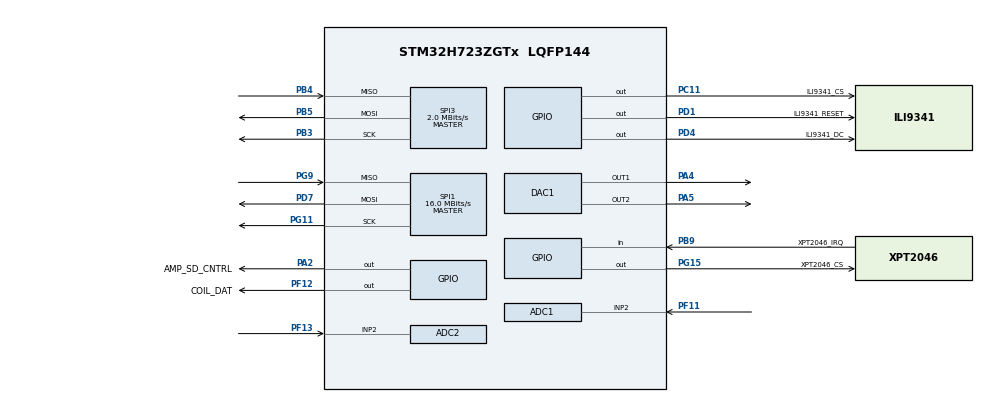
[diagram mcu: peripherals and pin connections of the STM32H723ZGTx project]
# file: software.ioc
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ADC1.Channel-0\#ChannelRegularConversion=ADC_CHANNEL_2
ADC1.ClockPrescaler=ADC_CLOCK_ASYNC_DIV2
ADC1.ConversionDataManagement=ADC_CONVERSIONDATA_DMA_CIRCULAR
ADC1.DMAAccessModeView=ENABLE
ADC1.ExternalTrigConv=ADC_EXTERNALTRIG_T2_TRGO
ADC1.Mode=ADC_DUALMODE_REGSIMULT
ADC1.NbrOfConversionFlag=1
ADC1.OffsetNumber-0\#ChannelRegularConversion=ADC_OFFSET_NONE
ADC1.OffsetSignedSaturation-0\#ChannelRegularConversion=DISABLE
ADC1.Rank-0\#ChannelRegularConversion=1
ADC1.Resolution=ADC_RESOLUTION_12B
ADC1.SamplingTime-0\#ChannelRegularConversion=ADC_SAMPLETIME_1CYCLE_5
ADC1.TwoSamplingDelay=ADC_TWOSAMPLINGDELAY_1CYCLE
ADC1.master=1
ADC2.Channel-0\#ChannelRegularConversion=ADC_CHANNEL_2
ADC2.ClockPrescaler=ADC_CLOCK_ASYNC_DIV2
ADC2.DMAAccessModeView=ENABLE
ADC2.Mode=ADC_DUALMODE_REGSIMULT
ADC2.NbrOfConversionFlag=1
ADC2.OffsetNumber-0\#ChannelRegularConversion=ADC_OFFSET_NONE
ADC2.OffsetSignedSaturation-0\#ChannelRegularConversion=DISABLE
ADC2.Rank-0\#ChannelRegularConversion=1
ADC2.Resolution=ADC_RESOLUTION_12B
ADC2.SamplingTime-0\#ChannelRegularConversion=ADC_SAMPLETIME_1CYCLE_5
CORTEX_M7.default_mode_Activation=1
DAC1.DAC1_OutputBuffer-DAC_OUT1=DAC_OUTPUTBUFFER_ENABLE
DAC1.DAC_Channel-DAC_OUT1=DAC_CHANNEL_1
DAC1.DAC_Channel-DAC_OUT2=DAC_CHANNEL_2
DAC1.DAC_Trigger-DAC_OUT1=DAC_TRIGGER_T2_TRGO
DAC1.DAC_Trigger-DAC_OUT2=DAC_TRIGGER_T2_TRGO
Dma.ADC1.0.Direction=DMA_PERIPH_TO_MEMORY
Dma.ADC1.0.EventEnable=DISABLE
Dma.ADC1.0.FIFOMode=DMA_FIFOMODE_DISABLE
Dma.ADC1.0.Instance=DMA1_Stream2
Dma.ADC1.0.MemDataAlignment=DMA_MDATAALIGN_WORD
Dma.ADC1.0.MemInc=DMA_MINC_ENABLE
Dma.ADC1.0.Mode=DMA_CIRCULAR
Dma.ADC1.0.PeriphDataAlignment=DMA_PDATAALIGN_WORD
Dma.ADC1.0.PeriphInc=DMA_PINC_DISABLE
Dma.ADC1.0.Polarity=HAL_DMAMUX_REQ_GEN_RISING
Dma.ADC1.0.Priority=DMA_PRIORITY_LOW
Dma.ADC1.0.RequestNumber=1
Dma.ADC1.0.SignalID=NONE
Dma.ADC1.0.SyncEnable=DISABLE
Dma.ADC1.0.SyncPolarity=HAL_DMAMUX_SYNC_NO_EVENT
Dma.ADC1.0.SyncRequestNumber=1
Dma.ADC1.0.SyncSignalID=NONE
Dma.DAC1_CH1.2.Direction=DMA_MEMORY_TO_PERIPH
Dma.DAC1_CH1.2.EventEnable=DISABLE
Dma.DAC1_CH1.2.FIFOMode=DMA_FIFOMODE_DISABLE
Dma.DAC1_CH1.2.Instance=DMA1_Stream0
Dma.DAC1_CH1.2.MemDataAlignment=DMA_MDATAALIGN_WORD
Dma.DAC1_CH1.2.MemInc=DMA_MINC_ENABLE
Dma.DAC1_CH1.2.Mode=DMA_CIRCULAR
Dma.DAC1_CH1.2.PeriphDataAlignment=DMA_PDATAALIGN_WORD
Dma.DAC1_CH1.2.PeriphInc=DMA_PINC_DISABLE
Dma.DAC1_CH1.2.Polarity=HAL_DMAMUX_REQ_GEN_RISING
Dma.DAC1_CH1.2.Priority=DMA_PRIORITY_LOW
Dma.DAC1_CH1.2.RequestNumber=1
Dma.DAC1_CH1.2.SignalID=NONE
Dma.DAC1_CH1.2.SyncEnable=DISABLE
Dma.DAC1_CH1.2.SyncPolarity=HAL_DMAMUX_SYNC_NO_EVENT
Dma.DAC1_CH1.2.SyncRequestNumber=1
Dma.DAC1_CH1.2.SyncSignalID=NONE
Dma.DAC1_CH2.3.Direction=DMA_MEMORY_TO_PERIPH
Dma.DAC1_CH2.3.EventEnable=DISABLE
Dma.DAC1_CH2.3.FIFOMode=DMA_FIFOMODE_DISABLE
Dma.DAC1_CH2.3.Instance=DMA1_Stream3
Dma.DAC1_CH2.3.MemDataAlignment=DMA_MDATAALIGN_WORD
Dma.DAC1_CH2.3.MemInc=DMA_MINC_ENABLE
Dma.DAC1_CH2.3.Mode=DMA_CIRCULAR
Dma.DAC1_CH2.3.PeriphDataAlignment=DMA_PDATAALIGN_WORD
Dma.DAC1_CH2.3.PeriphInc=DMA_PINC_DISABLE
Dma.DAC1_CH2.3.Polarity=HAL_DMAMUX_REQ_GEN_RISING
Dma.DAC1_CH2.3.Priority=DMA_PRIORITY_LOW
Dma.DAC1_CH2.3.RequestNumber=1
Dma.DAC1_CH2.3.SignalID=NONE
Dma.DAC1_CH2.3.SyncEnable=DISABLE
Dma.DAC1_CH2.3.SyncPolarity=HAL_DMAMUX_SYNC_NO_EVENT
Dma.DAC1_CH2.3.SyncRequestNumber=1
Dma.DAC1_CH2.3.SyncSignalID=NONE
Dma.Request0=ADC1
Dma.Request1=SPI1_TX
Dma.Request2=DAC1_CH1
Dma.Request3=DAC1_CH2
Dma.SPI1_TX.1.Direction=DMA_MEMORY_TO_PERIPH
Dma.SPI1_TX.1.EventEnable=DISABLE
Dma.SPI1_TX.1.FIFOMode=DMA_FIFOMODE_DISABLE
Dma.SPI1_TX.1.Instance=DMA1_Stream1
Dma.SPI1_TX.1.MemDataAlignment=DMA_MDATAALIGN_BYTE
Dma.SPI1_TX.1.MemInc=DMA_MINC_ENABLE
Dma.SPI1_TX.1.Mode=DMA_NORMAL
Dma.SPI1_TX.1.PeriphDataAlignment=DMA_PDATAALIGN_BYTE
Dma.SPI1_TX.1.PeriphInc=DMA_PINC_DISABLE
Dma.SPI1_TX.1.Polarity=HAL_DMAMUX_REQ_GEN_RISING
Dma.SPI1_TX.1.Priority=DMA_PRIORITY_LOW
Dma.SPI1_TX.1.RequestNumber=1
Dma.SPI1_TX.1.SignalID=NONE
Dma.SPI1_TX.1.SyncEnable=DISABLE
Dma.SPI1_TX.1.SyncPolarity=HAL_DMAMUX_SYNC_NO_EVENT
Dma.SPI1_TX.1.SyncRequestNumber=1
Dma.SPI1_TX.1.SyncSignalID=NONE
FREERTOS.BinarySemaphores01=AudioSemaphore,Static,AudioSemaphoreControlBlock,Available
FREERTOS.HEAP_NUMBER=4
FREERTOS.Mutexes01=LvMutex,Static,LvMutexControlBlock,Available
FREERTOS.Queues01=InputFlagQueue,1,uint32_t,0,Static,InputFlagQueueBuffer,InputFlagQueueControlBlock
FREERTOS.Tasks01=SignalProcessing,24,1000,SignalProcessingTask,As weak,NULL,Static,SignalProcessingBuffer,SignalProcessingControlBlock;ProduceAudio,23,128,ProduceAudioTask,As weak,NULL,Static,ProduceAudioBuffer,ProduceAudioControlBlock;lvHandler,48,5000,LvHandlerTask,As weak,NULL,Static,lvHandlerBuffer,lvHandlerControlBlock
FREERTOS.configMAX_TASK_NAME_LEN=24
FREERTOS.configUSE_IDLE_HOOK=0
FREERTOS.configUSE_NEWLIB_REENTRANT=1
Mcu.Family=STM32H7
Mcu.Name=STM32H723ZGTx
Mcu.Package=LQFP144
NVIC.DMA1_Stream0_IRQn=true\:14\:0\:true\:false\:true\:true\:false\:true\:true
NVIC.DMA1_Stream1_IRQn=true\:14\:0\:true\:false\:true\:true\:false\:true\:true
NVIC.DMA1_Stream2_IRQn=true\:14\:0\:true\:false\:true\:true\:false\:true\:true
NVIC.DMA1_Stream3_IRQn=true\:14\:0\:true\:false\:true\:true\:false\:true\:true
NVIC.PriorityGroup=NVIC_PRIORITYGROUP_4
NVIC.SPI1_IRQn=true\:14\:0\:true\:false\:true\:true\:false\:true\:true
NVIC.TIM1_UP_IRQn=true\:15\:0\:false\:false\:true\:false\:false\:true\:true
NVIC.TimeBase=TIM1_UP_IRQn
NVIC.TimeBaseIP=TIM1
PA13(JTMS/SWDIO).Mode=Serial_Wire
PA13(JTMS/SWDIO).Signal=DEBUG_JTMS-SWDIO
PA14(JTCK/SWCLK).Mode=Serial_Wire
PA14(JTCK/SWCLK).Signal=DEBUG_JTCK-SWCLK
PA2.GPIO_Label=AMP_SD_CNTRL
PA2.PinState=GPIO_PIN_RESET
PA2.Signal=GPIO_Output
PA4.Signal=COMP_DAC11_group
PA5.Signal=COMP_DAC12_group
PB3(JTDO/TRACESWO).Mode=Full_Duplex_Master
PB3(JTDO/TRACESWO).Signal=SPI3_SCK
PB4(NJTRST).Mode=Full_Duplex_Master
PB4(NJTRST).Signal=SPI3_MISO
PB5.Mode=Full_Duplex_Master
PB5.Signal=SPI3_MOSI
PB9.GPIO_Label=XPT2046_IRQ
PB9.GPIO_PuPd=GPIO_PULLUP
PB9.Signal=GPIO_Input
PC11.GPIO_Label=ILI9341_CS
PC11.PinState=GPIO_PIN_SET
PC11.Signal=GPIO_Output
PC14-OSC32_IN.Mode=LSE-External-Oscillator
PC14-OSC32_IN.Signal=RCC_OSC32_IN
PC15-OSC32_OUT.Mode=LSE-External-Oscillator
PC15-OSC32_OUT.Signal=RCC_OSC32_OUT
PD1.GPIO_Label=ILI9341_RESET
PD1.PinState=GPIO_PIN_SET
PD1.Signal=GPIO_Output
PD4.GPIO_Label=ILI9341_DC
PD4.PinState=GPIO_PIN_SET
PD4.Signal=GPIO_Output
PD7.Mode=Full_Duplex_Master
PD7.Signal=SPI1_MOSI
PF11.Mode=IN2-Single-Ended
PF11.Signal=ADC1_INP2
PF12.GPIO_Label=COIL_DAT
PF12.GPIO_Speed=GPIO_SPEED_FREQ_VERY_HIGH
PF12.Signal=GPIO_Output
PF13.Mode=IN2-Single-Ended
PF13.Signal=ADC2_INP2
PG11.Mode=Full_Duplex_Master
PG11.Signal=SPI1_SCK
PG15.GPIO_Label=XPT2046_CS
PG15.PinState=GPIO_PIN_SET
PG15.Signal=GPIO_Output
PG9.Mode=Full_Duplex_Master
PG9.Signal=SPI1_MISO
PH0-OSC_IN.Mode=HSE-External-Oscillator
PH0-OSC_IN.Signal=RCC_OSC_IN
PH1-OSC_OUT.Mode=HSE-External-Oscillator
PH1-OSC_OUT.Signal=RCC_OSC_OUT
ProjectManager.HeapSize=0x500
ProjectManager.StackSize=0x400
ProjectManager.TargetToolchain=STM32CubeIDE
RCC.ADCFreq_Value=50000000
RCC.APB1Freq_Value=137500000
RCC.APB2Freq_Value=137500000
RCC.APB3Freq_Value=137500000
RCC.APB4Freq_Value=137500000
RCC.CortexFreq_Value=550000000
RCC.D1PPRE=RCC_APB3_DIV2
RCC.D2PPRE1=RCC_APB1_DIV2
RCC.D2PPRE2=RCC_APB2_DIV2
RCC.D3PPRE=RCC_APB4_DIV2
RCC.DIVM1=2
RCC.DIVM2=2
RCC.DIVN1=44
RCC.DIVN2=16
RCC.DIVP1=1
RCC.DIVP2=4
RCC.DIVQ1=37
RCC.HCLKFreq_Value=275000000
RCC.HPRE=RCC_HCLK_DIV2
RCC.PLL2FRACN=0
RCC.PLL3FRACN=0
RCC.PLLFRACN=0
RCC.PLLSourceVirtual=RCC_PLLSOURCE_HSE
RCC.SPI123CLockSelection=RCC_SPI123CLKSOURCE_CLKP
RCC.SYSCLKFreq_VALUE=550000000
RCC.SYSCLKSource=RCC_SYSCLKSOURCE_PLLCLK
RCC.USBFreq_Value=14864864.864864865
SH.COMP_DAC11_group.0=DAC1_OUT1,DAC_OUT1
SH.COMP_DAC12_group.0=DAC1_OUT2,DAC_OUT2
SPI1.BaudRatePrescaler=SPI_BAUDRATEPRESCALER_4
SPI1.CalculateBaudRate=16.0 MBits/s
SPI1.DataSize=SPI_DATASIZE_8BIT
SPI1.Direction=SPI_DIRECTION_2LINES
SPI1.Mode=SPI_MODE_MASTER
SPI1.VirtualType=VM_MASTER
SPI3.BaudRatePrescaler=SPI_BAUDRATEPRESCALER_32
SPI3.CalculateBaudRate=2.0 MBits/s
SPI3.DataSize=SPI_DATASIZE_8BIT
SPI3.Direction=SPI_DIRECTION_2LINES
SPI3.Mode=SPI_MODE_MASTER
SPI3.VirtualType=VM_MASTER
STMicroelectronics.X-CUBE-ALGOBUILD.1.4.0.LibraryCcDSPOoLibraryJjDSPOoLibrary=true
TIM2.Period=1467-1
TIM2.Prescaler=0
TIM2.TIM_MasterOutputTrigger=TIM_TRGO_UPDATE
VP_FREERTOS_VS_CMSIS_V2.Mode=CMSIS_V2
VP_MEMORYMAP_VS_MEMORYMAP.Mode=CurAppReg
VP_STMicroelectronics.X-CUBE-ALGOBUILD_VS_DSPOoLibraryJjLibrary_1.4.0_1.4.0.Mode=DSPOoLibraryJjLibrary
VP_SYS_VS_tim1.Mode=TIM1
VP_TIM2_VS_ClockSourceINT.Mode=Internal
board=custom

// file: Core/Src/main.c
/* USER CODE BEGIN Header */
/**
  ******************************************************************************
  * @file           : main.c
  * @brief          : Main program body
  ******************************************************************************
  * @attention
  *
  * Copyright (c) 2024 STMicroelectronics.
  * All rights reserved.
  *
  * This software is licensed under terms that can be found in the LICENSE file
  * in the root directory of this software component.
  * If no LICENSE file comes with this software, it is provided AS-IS.
  *
  ******************************************************************************
  */
/* USER CODE END Header */
#include "main.h"
#include "cmsis_os.h"
#include "adc.h"
#include "dac.h"
#include "dma.h"
#include "memorymap.h"
#include "spi.h"
#include "tim.h"
#include "gpio.h"

/* USER CODE BEGIN Includes */

#include "lvgl.h"
#include "display.h"
#include "ui.h"

#include "app_signal.h"

/* USER CODE END Includes */

void SystemClock_Config(void);
void PeriphCommonClock_Config(void);
static void MPU_Config(void);
void MX_FREERTOS_Init(void);

int main(void)
{

  /* MPU Configuration--------------------------------------------------------*/
  MPU_Config();

  /* MCU Configuration--------------------------------------------------------*/

  /* Reset of all peripherals, Initializes the Flash interface and the Systick. */
  HAL_Init();

  /* Configure the system clock */
  SystemClock_Config();

  /* Configure the peripherals common clocks */
  PeriphCommonClock_Config();

  /* Initialize all configured peripherals */
  MX_GPIO_Init();
  MX_DMA_Init();
  MX_SPI3_Init();
  MX_ADC1_Init();
  MX_ADC2_Init();
  MX_DAC1_Init();
  MX_SPI1_Init();
  MX_TIM2_Init();
  /* USER CODE BEGIN 2 */

	dp_init();

	dp_lvgl_init();

	ui_init();

	sig_start(&sig_handle);

  /* USER CODE END 2 */

  /* Init scheduler */
  osKernelInitialize();

  /* Call init function for freertos objects (in cmsis_os2.c) */
  MX_FREERTOS_Init();

  /* Start scheduler */
  osKernelStart();

  /* We should never get here as control is now taken by the scheduler */

  /* Infinite loop */
  while (1)
  {

  }
}

void SystemClock_Config(void)
{
  RCC_OscInitTypeDef RCC_OscInitStruct = {0};
  RCC_ClkInitTypeDef RCC_ClkInitStruct = {0};

  /** Supply configuration update enable
  */
  HAL_PWREx_ConfigSupply(PWR_LDO_SUPPLY);

  /** Configure the main internal regulator output voltage
  */
  __HAL_PWR_VOLTAGESCALING_CONFIG(PWR_REGULATOR_VOLTAGE_SCALE0);

  while(!__HAL_PWR_GET_FLAG(PWR_FLAG_VOSRDY)) {}

  /** Initializes the RCC Oscillators according to the specified parameters
  * in the RCC_OscInitTypeDef structure.
  */
  RCC_OscInitStruct.OscillatorType = RCC_OSCILLATORTYPE_HSI|RCC_OSCILLATORTYPE_HSE;
  RCC_OscInitStruct.HSEState = RCC_HSE_ON;
  RCC_OscInitStruct.HSIState = RCC_HSI_DIV1;
  RCC_OscInitStruct.HSICalibrationValue = 64;
  RCC_OscInitStruct.PLL.PLLState = RCC_PLL_ON;
  RCC_OscInitStruct.PLL.PLLSource = RCC_PLLSOURCE_HSE;
  RCC_OscInitStruct.PLL.PLLM = 2;
  RCC_OscInitStruct.PLL.PLLN = 44;
  RCC_OscInitStruct.PLL.PLLP = 1;
  RCC_OscInitStruct.PLL.PLLQ = 37;
  RCC_OscInitStruct.PLL.PLLR = 2;
  RCC_OscInitStruct.PLL.PLLRGE = RCC_PLL1VCIRANGE_3;
  RCC_OscInitStruct.PLL.PLLVCOSEL = RCC_PLL1VCOWIDE;
  RCC_OscInitStruct.PLL.PLLFRACN = 0;
  if (HAL_RCC_OscConfig(&RCC_OscInitStruct) != HAL_OK)
  {
    Error_Handler();
  }

  /** Initializes the CPU, AHB and APB buses clocks
  */
  RCC_ClkInitStruct.ClockType = RCC_CLOCKTYPE_HCLK|RCC_CLOCKTYPE_SYSCLK
                              |RCC_CLOCKTYPE_PCLK1|RCC_CLOCKTYPE_PCLK2
                              |RCC_CLOCKTYPE_D3PCLK1|RCC_CLOCKTYPE_D1PCLK1;
  RCC_ClkInitStruct.SYSCLKSource = RCC_SYSCLKSOURCE_PLLCLK;
  RCC_ClkInitStruct.SYSCLKDivider = RCC_SYSCLK_DIV1;
  RCC_ClkInitStruct.AHBCLKDivider = RCC_HCLK_DIV2;
  RCC_ClkInitStruct.APB3CLKDivider = RCC_APB3_DIV2;
  RCC_ClkInitStruct.APB1CLKDivider = RCC_APB1_DIV2;
  RCC_ClkInitStruct.APB2CLKDivider = RCC_APB2_DIV2;
  RCC_ClkInitStruct.APB4CLKDivider = RCC_APB4_DIV2;

  if (HAL_RCC_ClockConfig(&RCC_ClkInitStruct, FLASH_LATENCY_3) != HAL_OK)
  {
    Error_Handler();
  }
}

void PeriphCommonClock_Config(void)
{
  RCC_PeriphCLKInitTypeDef PeriphClkInitStruct = {0};

  /** Initializes the peripherals clock
  */
  PeriphClkInitStruct.PeriphClockSelection = RCC_PERIPHCLK_ADC|RCC_PERIPHCLK_CKPER;
  PeriphClkInitStruct.PLL2.PLL2M = 2;
  PeriphClkInitStruct.PLL2.PLL2N = 16;
  PeriphClkInitStruct.PLL2.PLL2P = 4;
  PeriphClkInitStruct.PLL2.PLL2Q = 2;
  PeriphClkInitStruct.PLL2.PLL2R = 2;
  PeriphClkInitStruct.PLL2.PLL2RGE = RCC_PLL2VCIRANGE_3;
  PeriphClkInitStruct.PLL2.PLL2VCOSEL = RCC_PLL2VCOWIDE;
  PeriphClkInitStruct.PLL2.PLL2FRACN = 0;
  PeriphClkInitStruct.CkperClockSelection = RCC_CLKPSOURCE_HSI;
  PeriphClkInitStruct.AdcClockSelection = RCC_ADCCLKSOURCE_PLL2;
  if (HAL_RCCEx_PeriphCLKConfig(&PeriphClkInitStruct) != HAL_OK)
  {
    Error_Handler();
  }
}

/* USER CODE BEGIN 4 */

void HAL_SPI_TxCpltCallback(SPI_HandleTypeDef *hspi)
{
	if( hspi == ili9341_spi )
	{
		ILI9341_SPICmpltHandler();
	}
}

/* USER CODE END 4 */

 /* MPU Configuration */

void MPU_Config(void)
{
  MPU_Region_InitTypeDef MPU_InitStruct = {0};

  /* Disables the MPU */
  HAL_MPU_Disable();

  /** Initializes and configures the Region and the memory to be protected
  */
  MPU_InitStruct.Enable = MPU_REGION_ENABLE;
  MPU_InitStruct.Number = MPU_REGION_NUMBER0;
  MPU_InitStruct.BaseAddress = 0x0;
  MPU_InitStruct.Size = MPU_REGION_SIZE_4GB;
  MPU_InitStruct.SubRegionDisable = 0x87;
  MPU_InitStruct.TypeExtField = MPU_TEX_LEVEL0;
  MPU_InitStruct.AccessPermission = MPU_REGION_NO_ACCESS;
  MPU_InitStruct.DisableExec = MPU_INSTRUCTION_ACCESS_DISABLE;
  MPU_InitStruct.IsShareable = MPU_ACCESS_SHAREABLE;
  MPU_InitStruct.IsCacheable = MPU_ACCESS_NOT_CACHEABLE;
  MPU_InitStruct.IsBufferable = MPU_ACCESS_NOT_BUFFERABLE;

  HAL_MPU_ConfigRegion(&MPU_InitStruct);
  /* Enables the MPU */
  HAL_MPU_Enable(MPU_PRIVILEGED_DEFAULT);

}

void HAL_TIM_PeriodElapsedCallback(TIM_HandleTypeDef *htim)
{
  if (htim->Instance == TIM1) {
    HAL_IncTick();
  }
}

void Error_Handler(void)
{
  __disable_irq();
  while (1)
  {
  }
}

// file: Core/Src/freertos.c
/* USER CODE BEGIN Header */
/**
  ******************************************************************************
  * File Name          : freertos.c
  * Description        : Code for freertos applications
  ******************************************************************************
  * @attention
  *
  * Copyright (c) 2024 STMicroelectronics.
  * All rights reserved.
  *
  * This software is licensed under terms that can be found in the LICENSE file
  * in the root directory of this software component.
  * If no LICENSE file comes with this software, it is provided AS-IS.
  *
  ******************************************************************************
  */
/* USER CODE END Header */

#include "FreeRTOS.h"
#include "task.h"
#include "main.h"
#include "cmsis_os.h"

typedef StaticTask_t osStaticThreadDef_t;
typedef StaticQueue_t osStaticMessageQDef_t;
typedef StaticSemaphore_t osStaticMutexDef_t;
typedef StaticSemaphore_t osStaticSemaphoreDef_t;

/* USER CODE BEGIN PM */

#define MS_TO_TICKS(ms) ((ms * osKernelGetTickFreq()) / 1000)

/* USER CODE END PM */

/* Definitions for SignalProcessing */
osThreadId_t SignalProcessingHandle;
uint32_t SignalProcessingBuffer[ 1000 ];
osStaticThreadDef_t SignalProcessingControlBlock;
const osThreadAttr_t SignalProcessing_attributes = {
  .name = "SignalProcessing",
  .cb_mem = &SignalProcessingControlBlock,
  .cb_size = sizeof(SignalProcessingControlBlock),
  .stack_mem = &SignalProcessingBuffer[0],
  .stack_size = sizeof(SignalProcessingBuffer),
  .priority = (osPriority_t) osPriorityNormal,
};
/* Definitions for ProduceAudio */
osThreadId_t ProduceAudioHandle;
uint32_t ProduceAudioBuffer[ 128 ];
osStaticThreadDef_t ProduceAudioControlBlock;
const osThreadAttr_t ProduceAudio_attributes = {
  .name = "ProduceAudio",
  .cb_mem = &ProduceAudioControlBlock,
  .cb_size = sizeof(ProduceAudioControlBlock),
  .stack_mem = &ProduceAudioBuffer[0],
  .stack_size = sizeof(ProduceAudioBuffer),
  .priority = (osPriority_t) osPriorityBelowNormal7,
};
/* Definitions for lvHandler */
osThreadId_t lvHandlerHandle;
uint32_t lvHandlerBuffer[ 5000 ];
osStaticThreadDef_t lvHandlerControlBlock;
const osThreadAttr_t lvHandler_attributes = {
  .name = "lvHandler",
  .cb_mem = &lvHandlerControlBlock,
  .cb_size = sizeof(lvHandlerControlBlock),
  .stack_mem = &lvHandlerBuffer[0],
  .stack_size = sizeof(lvHandlerBuffer),
  .priority = (osPriority_t) osPriorityRealtime,
};
/* Definitions for InputFlagQueue */
osMessageQueueId_t InputFlagQueueHandle;
uint8_t InputFlagQueueBuffer[ 1 * sizeof( uint32_t ) ];
osStaticMessageQDef_t InputFlagQueueControlBlock;
const osMessageQueueAttr_t InputFlagQueue_attributes = {
  .name = "InputFlagQueue",
  .cb_mem = &InputFlagQueueControlBlock,
  .cb_size = sizeof(InputFlagQueueControlBlock),
  .mq_mem = &InputFlagQueueBuffer,
  .mq_size = sizeof(InputFlagQueueBuffer)
};
/* Definitions for LvMutex */
osMutexId_t LvMutexHandle;
osStaticMutexDef_t LvMutexControlBlock;
const osMutexAttr_t LvMutex_attributes = {
  .name = "LvMutex",
  .cb_mem = &LvMutexControlBlock,
  .cb_size = sizeof(LvMutexControlBlock),
};
/* Definitions for AudioSemaphore */
osSemaphoreId_t AudioSemaphoreHandle;
osStaticSemaphoreDef_t AudioSemaphoreControlBlock;
const osSemaphoreAttr_t AudioSemaphore_attributes = {
  .name = "AudioSemaphore",
  .cb_mem = &AudioSemaphoreControlBlock,
  .cb_size = sizeof(AudioSemaphoreControlBlock),
};

void SignalProcessingTask(void *argument);
void ProduceAudioTask(void *argument);
void LvHandlerTask(void *argument);

void MX_FREERTOS_Init(void); /* (MISRA C 2004 rule 8.1) */

void MX_FREERTOS_Init(void) {
  /* Create the mutex(es) */
  /* creation of LvMutex */
  LvMutexHandle = osMutexNew(&LvMutex_attributes);

  /* Create the semaphores(s) */
  /* creation of AudioSemaphore */
  AudioSemaphoreHandle = osSemaphoreNew(1, 1, &AudioSemaphore_attributes);

  /* Create the queue(s) */
  /* creation of InputFlagQueue */
  InputFlagQueueHandle = osMessageQueueNew (1, sizeof(uint32_t), &InputFlagQueue_attributes);

  /* Create the thread(s) */
  /* creation of SignalProcessing */
  SignalProcessingHandle = osThreadNew(SignalProcessingTask, NULL, &SignalProcessing_attributes);

  /* creation of ProduceAudio */
  ProduceAudioHandle = osThreadNew(ProduceAudioTask, NULL, &ProduceAudio_attributes);

  /* creation of lvHandler */
  lvHandlerHandle = osThreadNew(LvHandlerTask, NULL, &lvHandler_attributes);

}

__weak void SignalProcessingTask(void *argument)
{
  for(;;)
  {
    osDelay(1);
  }
}

__weak void ProduceAudioTask(void *argument)
{
  for(;;)
  {
    osDelay(1);
  }
}

__weak void LvHandlerTask(void *argument)
{
  for(;;)
  {
    osDelay(1);
  }
}
